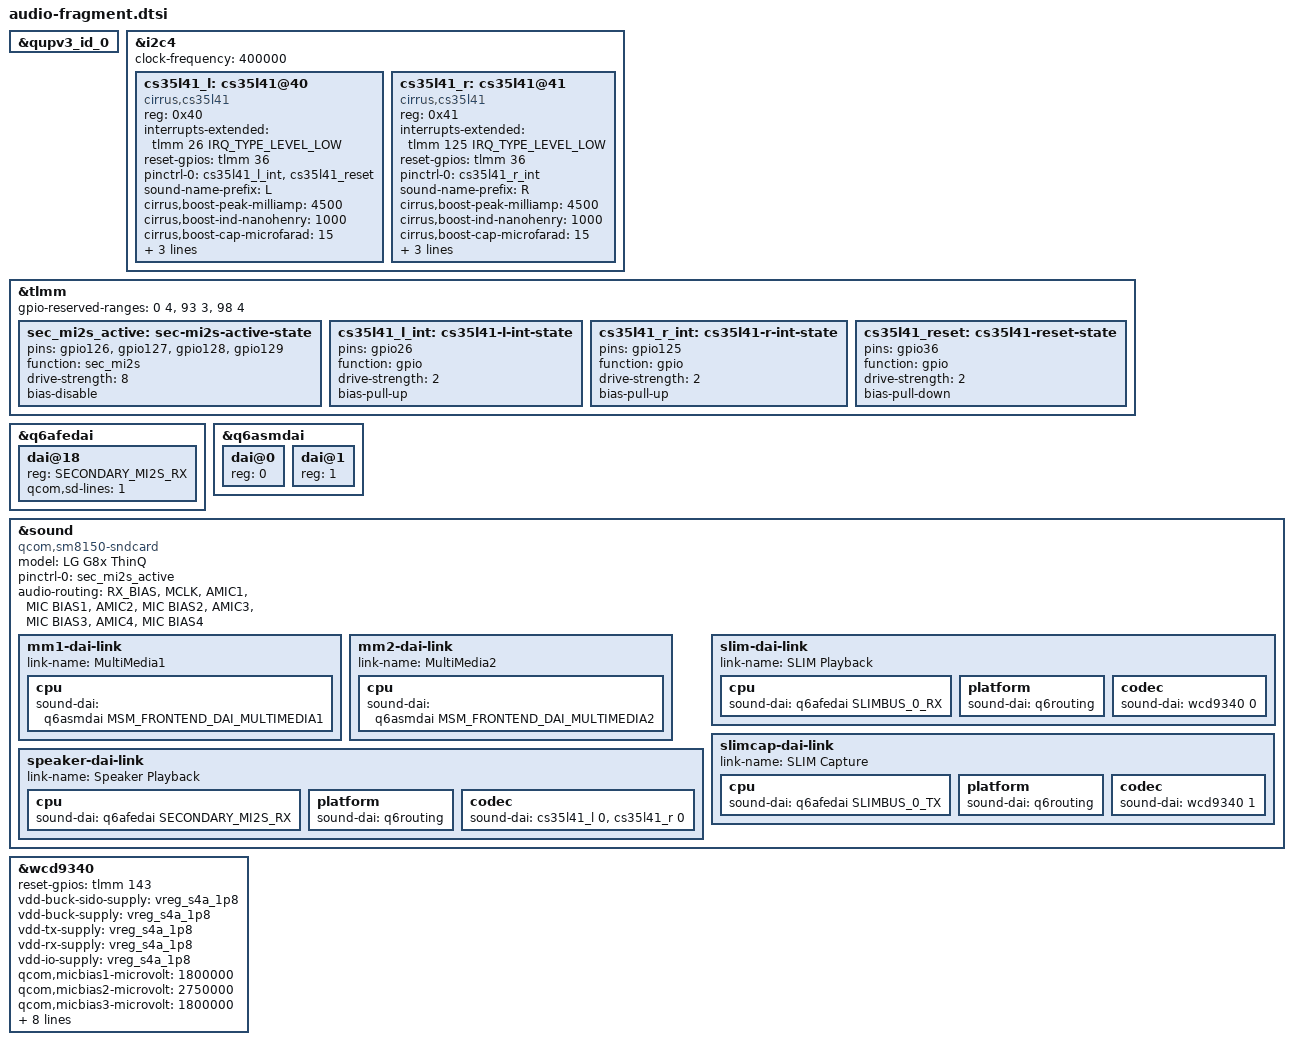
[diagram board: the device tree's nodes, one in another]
#include <dt-bindings/sound/qcom,q6asm.h>
#include <dt-bindings/sound/qcom,q6dsp-lpass-ports.h>
#include "sm8150-wcd9340.dtsi"

/* Speakers: two Cirrus CS35L41 amps on QUP SE4 I2C, secondary MI2S.
 * Left amp = bottom speaker, right amp = earpiece used as second speaker.
 * (LG sm8150-mh2lm_common-sound-cs35l41.dtsi.) LG drives gpio126-129 as
 * sec_mi2s (sck, ws, sd0, sd1), so they are not reserved on this phone. */
&qupv3_id_0 {
	status = "okay";
};

&i2c4 {
	status = "okay";
	clock-frequency = <400000>;

	cs35l41_l: cs35l41@40 {
		compatible = "cirrus,cs35l41";
		reg = <0x40>;
		interrupts-extended = <&tlmm 26 IRQ_TYPE_LEVEL_LOW>;
		reset-gpios = <&tlmm 36 GPIO_ACTIVE_HIGH>;
		pinctrl-names = "default";
		pinctrl-0 = <&cs35l41_l_int>, <&cs35l41_reset>;
		#sound-dai-cells = <1>;
		sound-name-prefix = "L";
		cirrus,boost-peak-milliamp = <4500>;
		cirrus,boost-ind-nanohenry = <1000>;
		cirrus,boost-cap-microfarad = <15>;
		cirrus,asp-sdout-hiz = <3>;
		cirrus,gpio2-src-select = <4>;
		cirrus,gpio2-output-enable;
	};

	cs35l41_r: cs35l41@41 {
		compatible = "cirrus,cs35l41";
		reg = <0x41>;
		interrupts-extended = <&tlmm 125 IRQ_TYPE_LEVEL_LOW>;
		reset-gpios = <&tlmm 36 GPIO_ACTIVE_HIGH>;
		pinctrl-names = "default";
		pinctrl-0 = <&cs35l41_r_int>;
		#sound-dai-cells = <1>;
		sound-name-prefix = "R";
		cirrus,boost-peak-milliamp = <4500>;
		cirrus,boost-ind-nanohenry = <1000>;
		cirrus,boost-cap-microfarad = <15>;
		cirrus,asp-sdout-hiz = <3>;
		cirrus,gpio2-src-select = <4>;
		cirrus,gpio2-output-enable;
	};
};

&tlmm {
	gpio-reserved-ranges = <0 4>, <93 3>, <98 4>;

	sec_mi2s_active: sec-mi2s-active-state {
		pins = "gpio126", "gpio127", "gpio128", "gpio129";
		function = "sec_mi2s";
		drive-strength = <8>;
		bias-disable;
	};

	cs35l41_l_int: cs35l41-l-int-state {
		pins = "gpio26";
		function = "gpio";
		drive-strength = <2>;
		bias-pull-up;
	};

	cs35l41_r_int: cs35l41-r-int-state {
		pins = "gpio125";
		function = "gpio";
		drive-strength = <2>;
		bias-pull-up;
	};

	cs35l41_reset: cs35l41-reset-state {
		pins = "gpio36";
		function = "gpio";
		drive-strength = <2>;
		bias-pull-down;
	};
};

&q6afedai {
	dai@18 {
		reg = <SECONDARY_MI2S_RX>;
		qcom,sd-lines = <1>;	/* SD1 is the speaker data line (LG rx-lines = <2>) */
	};
};

&q6asmdai {
	dai@0 {
		reg = <0>;
	};

	dai@1 {
		reg = <1>;
	};
};

&sound {
	compatible = "qcom,sm8150-sndcard";
	model = "LG G8x ThinQ";
	pinctrl-0 = <&sec_mi2s_active>;
	pinctrl-names = "default";

	/* mic bias routing from LG sm8150-mh2lm_common-sound.dtsi.
	 * No "MultiMedia1 Playback" <- "L/R SPK" pairs (removed 2026-11-14):
	 * routes are (sink, source), so they fed the speaker outputs back into
	 * the front-end DAI and closed a loop that DAPM kept powered with no
	 * stream open: an AFE port running in the ADSP (no ADSP sleep, so no
	 * SoC deep sleep) and both CS35L41 amps with their boost on. */
	audio-routing = "RX_BIAS", "MCLK",
			"AMIC1", "MIC BIAS1",
			"AMIC2", "MIC BIAS2",
			"AMIC3", "MIC BIAS3",
			"AMIC4", "MIC BIAS4";

	mm1-dai-link {
		link-name = "MultiMedia1";
		cpu {
			sound-dai = <&q6asmdai MSM_FRONTEND_DAI_MULTIMEDIA1>;
		};
	};

	mm2-dai-link {
		link-name = "MultiMedia2";
		cpu {
			sound-dai = <&q6asmdai MSM_FRONTEND_DAI_MULTIMEDIA2>;
		};
	};

	speaker-dai-link {
		link-name = "Speaker Playback";
		cpu {
			sound-dai = <&q6afedai SECONDARY_MI2S_RX>;
		};

		platform {
			sound-dai = <&q6routing>;
		};

		codec {
			sound-dai = <&cs35l41_l 0>, <&cs35l41_r 0>;
		};
	};

	/* 3.5 mm headphones through the WCD9340 (LG: SLIM RX0 MUX = AIF1_PB) */
	slim-dai-link {
		link-name = "SLIM Playback";
		cpu {
			sound-dai = <&q6afedai SLIMBUS_0_RX>;
		};

		platform {
			sound-dai = <&q6routing>;
		};

		codec {
			sound-dai = <&wcd9340 0>; /* AIF1_PB */
		};
	};

	/* AMIC1 handset mic, AMIC2 headset mic, AMIC3 second mic */
	slimcap-dai-link {
		link-name = "SLIM Capture";
		cpu {
			sound-dai = <&q6afedai SLIMBUS_0_TX>;
		};

		platform {
			sound-dai = <&q6routing>;
		};

		codec {
			sound-dai = <&wcd9340 1>; /* AIF1_CAP */
		};
	};
};

&wcd9340 {
	reset-gpios = <&tlmm 143 GPIO_ACTIVE_HIGH>;
	vdd-buck-sido-supply = <&vreg_s4a_1p8>;
	vdd-buck-supply = <&vreg_s4a_1p8>;
	vdd-tx-supply = <&vreg_s4a_1p8>;
	vdd-rx-supply = <&vreg_s4a_1p8>;
	vdd-io-supply = <&vreg_s4a_1p8>;

	qcom,micbias1-microvolt = <1800000>;
	qcom,micbias2-microvolt = <2750000>;
	qcom,micbias3-microvolt = <1800000>;
	qcom,micbias4-microvolt = <1800000>;

	/* LG: qcom,msm-mbhc-hphl-swh = <1>, gnd-swh = <0> */
	qcom,ground-jack-type-normally-closed;
	qcom,mbhc-buttons-vthreshold-microvolt = <75000 150000 237000 500000 500000 500000 500000 500000>;
	qcom,mbhc-headset-vthreshold-microvolt = <1700000>;
	qcom,mbhc-headphone-vthreshold-microvolt = <50000>;
};
